# i2c register map
Vendor: Texas Instruments
Peripheral module from a debugger description file (folder cc32).
Registers are 32-bit, access not given, no defined reset value unless marked. A register's access mark holds for its fields unless they carry their own. Offsets are as the file gives them; lines under a group give offsets from that group; [hi:lo] are bit positions; {n}, {i} and the like mark numbered series; 'fields as' and 'values as' point back to an identical list; <NAME> marks a mode.

## i2c
0x00 MSA rw
  [7:1] SA — I2C Slave Address
0x04 MCS
0x08 MDR rw
  [7:0] DATA — Data Transferred
0x0C MTPR rw
  [6:0] TPR — SCL Clock Period
0x10 MIMR
0x14 MRIS
0x18 MMIS
0x1C MICR
0x20 MCR
0x24 MCLKOCNT rw
  [7:0] CNTL — I2C Master Count
0x2C MBMON
0x30 MBLEN rw
  [7:0] CNTL — I2C Burst Length
0x34 MBCNT rw
  [7:0] CNTL — I2C Master Burst Count
0x800 SOAR rw
  [6:0] OAR — I2C Slave Own Address
0x804 SCSR
0x808 SDR rw
  [7:0] DATA — Data for Transfer
0x80C SIMR
0x810 SRIS
0x814 SMIS
0x818 SICR
0x81C SOAR2 rw
  [6:0] OAR2 — I2C Slave Own Address 2
0x820 SACKCTL
0xF00 FIFODATA rw
  [7:0] DATA — I2C FIFO Data Byte
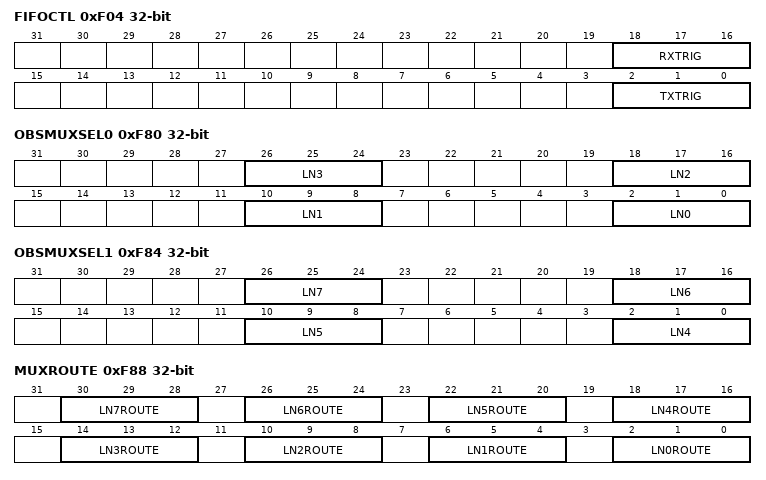
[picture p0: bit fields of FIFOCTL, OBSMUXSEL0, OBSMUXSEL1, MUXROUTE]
0xF04 FIFOCTL rw
  [18:16] RXTRIG — RX FIFO Trigger
  [2:0] TXTRIG — TX FIFO Trigger
0xF08 FIFOSTATUS
0xF80 OBSMUXSEL0 rw
  [8n+2:8n] LN{n} (n=0..3) — Observation Mux Lane {n}
0xF84 OBSMUXSEL1 rw
  [8n-30:8n-32] LN{n} (n=4..7) — Observation Mux Lane {n}
0xF88 MUXROUTE rw
  [4n+2:4n] LN{n}ROUTE (n=0..7) — Lane {n} output is routed to the lane pointed to by the offset in this bit field
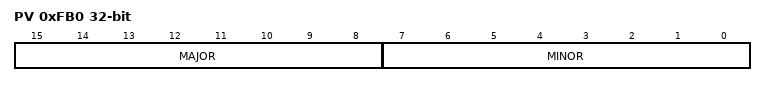
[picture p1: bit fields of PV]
0xFB0 PV rw
  [15:8] MAJOR — Major Revision
  [7:0] MINOR — Minor Revision
0xFC0 PP
0xFC4 PC
0xFC8 CC
